# ESP32-H4 register map
Vendor: ESPRESSIF SYSTEMS (SHANGHAI) CO., LTD.; Series: ESP32 H-Series; File version: 1
CPU: RV32IMAC r0p0, little endian, no MPU, no FPU, 0 interrupt priority bits
Address unit: 32 bits
Registers are 32-bit, read-write, reset 0x0 unless marked. A register's access mark holds for its fields unless they carry their own. Offsets are from the block's base; [hi:lo] are bit positions.

## MODEM_SYSCON
Base 0x600C9C00
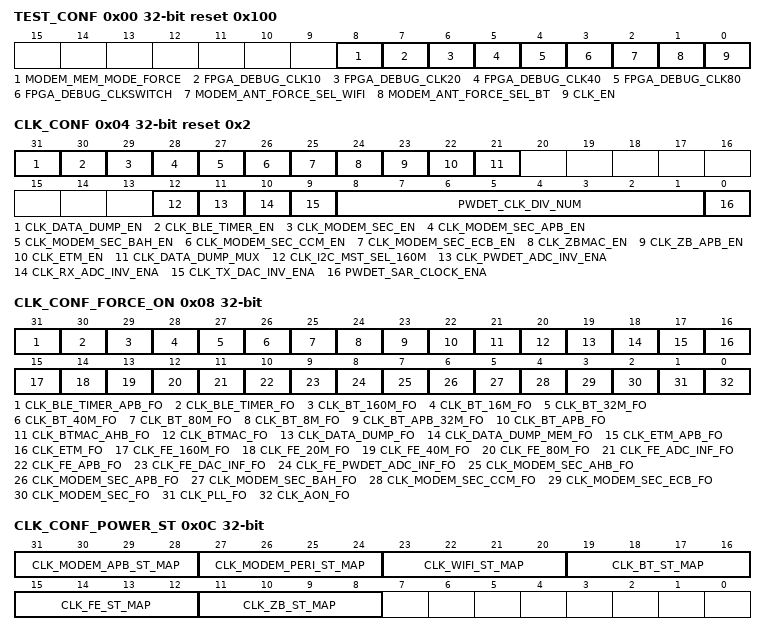
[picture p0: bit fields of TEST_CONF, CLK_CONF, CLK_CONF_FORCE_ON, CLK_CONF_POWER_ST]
0x00 TEST_CONF reset 0x100
  [8] MODEM_MEM_MODE_FORCE, [7] FPGA_DEBUG_CLK10, [6] FPGA_DEBUG_CLK20, [5] FPGA_DEBUG_CLK40, [4] FPGA_DEBUG_CLK80, [3] FPGA_DEBUG_CLKSWITCH, [2] MODEM_ANT_FORCE_SEL_WIFI, [1] MODEM_ANT_FORCE_SEL_BT, [0] CLK_EN
0x04 CLK_CONF reset 0x2
  [31] CLK_DATA_DUMP_EN, [30] CLK_BLE_TIMER_EN, [29] CLK_MODEM_SEC_EN, [28] CLK_MODEM_SEC_APB_EN, [27] CLK_MODEM_SEC_BAH_EN, [26] CLK_MODEM_SEC_CCM_EN, [25] CLK_MODEM_SEC_ECB_EN, [24] CLK_ZBMAC_EN, [23] CLK_ZB_APB_EN, [22] CLK_ETM_EN, [21] CLK_DATA_DUMP_MUX, [12] CLK_I2C_MST_SEL_160M, [11] CLK_PWDET_ADC_INV_ENA, [10] CLK_RX_ADC_INV_ENA, [9] CLK_TX_DAC_INV_ENA, [8:1] PWDET_CLK_DIV_NUM, [0] PWDET_SAR_CLOCK_ENA
0x08 CLK_CONF_FORCE_ON
  [31] CLK_BLE_TIMER_APB_FO, [30] CLK_BLE_TIMER_FO, [29] CLK_BT_160M_FO, [28] CLK_BT_16M_FO, [27] CLK_BT_32M_FO, [26] CLK_BT_40M_FO, [25] CLK_BT_80M_FO, [24] CLK_BT_8M_FO, [23] CLK_BT_APB_32M_FO, [22] CLK_BT_APB_FO, [21] CLK_BTMAC_AHB_FO, [20] CLK_BTMAC_FO, [19] CLK_DATA_DUMP_FO, [18] CLK_DATA_DUMP_MEM_FO, [17] CLK_ETM_APB_FO, [16] CLK_ETM_FO, [15] CLK_FE_160M_FO, [14] CLK_FE_20M_FO, [13] CLK_FE_40M_FO, [12] CLK_FE_80M_FO, [11] CLK_FE_ADC_INF_FO, [10] CLK_FE_APB_FO, [9] CLK_FE_DAC_INF_FO, [8] CLK_FE_PWDET_ADC_INF_FO, [7] CLK_MODEM_SEC_AHB_FO, [6] CLK_MODEM_SEC_APB_FO, [5] CLK_MODEM_SEC_BAH_FO, [4] CLK_MODEM_SEC_CCM_FO, [3] CLK_MODEM_SEC_ECB_FO, [2] CLK_MODEM_SEC_FO, [1] CLK_PLL_FO, [0] CLK_AON_FO
0x0C CLK_CONF_POWER_ST
  [31:28] CLK_MODEM_APB_ST_MAP, [27:24] CLK_MODEM_PERI_ST_MAP, [23:20] CLK_WIFI_ST_MAP, [19:16] CLK_BT_ST_MAP, [15:12] CLK_FE_ST_MAP, [11:8] CLK_ZB_ST_MAP
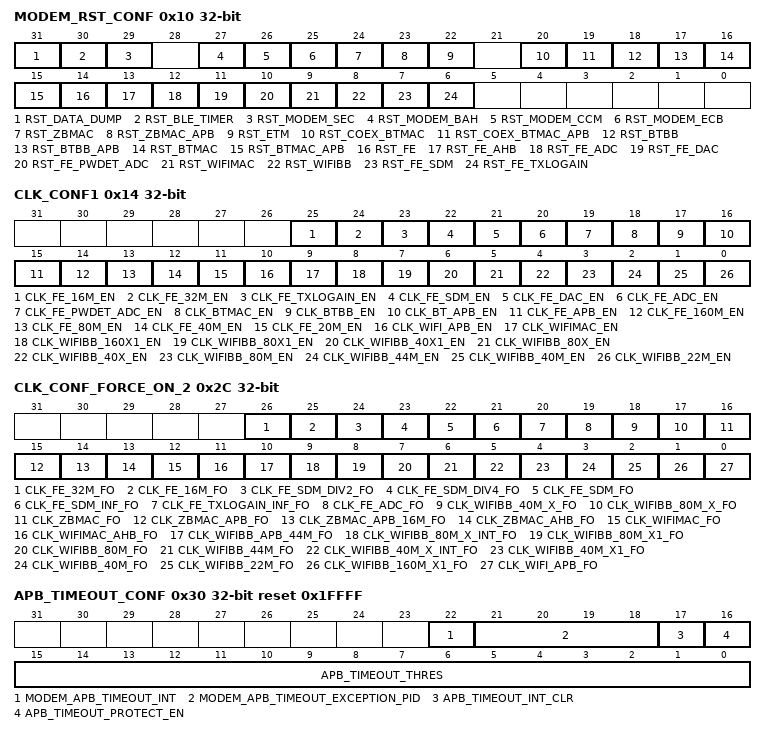
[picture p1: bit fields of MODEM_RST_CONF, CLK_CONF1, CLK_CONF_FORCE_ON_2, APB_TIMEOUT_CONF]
0x10 MODEM_RST_CONF
  [31] RST_DATA_DUMP, [30] RST_BLE_TIMER, [29] RST_MODEM_SEC, [27] RST_MODEM_BAH, [26] RST_MODEM_CCM, [25] RST_MODEM_ECB, [24] RST_ZBMAC, [23] RST_ZBMAC_APB, [22] RST_ETM, [20] RST_COEX_BTMAC, [19] RST_COEX_BTMAC_APB, [18] RST_BTBB, [17] RST_BTBB_APB, [16] RST_BTMAC, [15] RST_BTMAC_APB, [14] RST_FE, [13] RST_FE_AHB, [12] RST_FE_ADC, [11] RST_FE_DAC, [10] RST_FE_PWDET_ADC, [9] RST_WIFIMAC, [8] RST_WIFIBB, [7] RST_FE_SDM, [6] RST_FE_TXLOGAIN
0x14 CLK_CONF1
  [25] CLK_FE_16M_EN, [24] CLK_FE_32M_EN, [23] CLK_FE_TXLOGAIN_EN, [22] CLK_FE_SDM_EN, [21] CLK_FE_DAC_EN, [20] CLK_FE_ADC_EN, [19] CLK_FE_PWDET_ADC_EN, [18] CLK_BTMAC_EN, [17] CLK_BTBB_EN, [16] CLK_BT_APB_EN, [15] CLK_FE_APB_EN, [14] CLK_FE_160M_EN, [13] CLK_FE_80M_EN, [12] CLK_FE_40M_EN, [11] CLK_FE_20M_EN, [10] CLK_WIFI_APB_EN, [9] CLK_WIFIMAC_EN, [8] CLK_WIFIBB_160X1_EN, [7] CLK_WIFIBB_80X1_EN, [6] CLK_WIFIBB_40X1_EN, [5] CLK_WIFIBB_80X_EN, [4] CLK_WIFIBB_40X_EN, [3] CLK_WIFIBB_80M_EN, [2] CLK_WIFIBB_44M_EN, [1] CLK_WIFIBB_40M_EN, [0] CLK_WIFIBB_22M_EN
0x18 WIFI_BB_CFG
0x1C FE_CFG
0x20 MEM_RF1_CONF reset 0x2070
  [31:0] MODEM_RF1_MEM_AUX_CTRL
0x24 MEM_RF2_CONF
  [31:0] MODEM_RF2_MEM_AUX_CTRL
0x28 BTMAC_CLK_CFG
  [0] CLK_BTMAC_LOW_RATE
0x2C CLK_CONF_FORCE_ON_2
  [26] CLK_FE_32M_FO, [25] CLK_FE_16M_FO, [24] CLK_FE_SDM_DIV2_FO, [23] CLK_FE_SDM_DIV4_FO, [22] CLK_FE_SDM_FO, [21] CLK_FE_SDM_INF_FO, [20] CLK_FE_TXLOGAIN_INF_FO, [19] CLK_FE_ADC_FO, [18] CLK_WIFIBB_40M_X_FO, [17] CLK_WIFIBB_80M_X_FO, [16] CLK_ZBMAC_FO, [15] CLK_ZBMAC_APB_FO, [14] CLK_ZBMAC_APB_16M_FO, [13] CLK_ZBMAC_AHB_FO, [12] CLK_WIFIMAC_FO, [11] CLK_WIFIMAC_AHB_FO, [10] CLK_WIFIBB_APB_44M_FO, [9] CLK_WIFIBB_80M_X_INT_FO, [8] CLK_WIFIBB_80M_X1_FO, [7] CLK_WIFIBB_80M_FO, [6] CLK_WIFIBB_44M_FO, [5] CLK_WIFIBB_40M_X_INT_FO, [4] CLK_WIFIBB_40M_X1_FO, [3] CLK_WIFIBB_40M_FO, [2] CLK_WIFIBB_22M_FO, [1] CLK_WIFIBB_160M_X1_FO, [0] CLK_WIFI_APB_FO
0x30 APB_TIMEOUT_CONF reset 0x1FFFF
  [22] MODEM_APB_TIMEOUT_INT ro, [21:18] MODEM_APB_TIMEOUT_EXCEPTION_PID ro, [17] APB_TIMEOUT_INT_CLR wo, [16] APB_TIMEOUT_PROTECT_EN, [15:0] APB_TIMEOUT_THRES
0x34 APB_TIMEOUT_EXCEPTION_ADDR ro
  [31:0] MODEM_APB_TIMEOUT_EXCEPTION_PADDR
0x38 DATE
